VERSION "1.0"

NS_ :

BS_:
BU_:

CM_ "For Preparatory CareFree Awning Messages
Author: Damiano Liviero
for Winnebago Industries Inc.
";

CM_ "1FDCD";
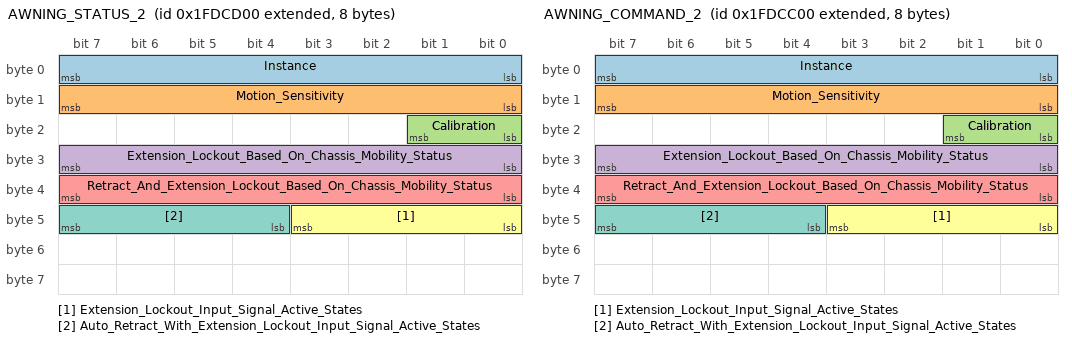
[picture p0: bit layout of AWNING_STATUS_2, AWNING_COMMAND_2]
BO_ 2180893952 AWNING_STATUS_2: 8  Vector__XXX
    SG_ Instance:        0|8@1+  (1,0)   [0|255] ""    Vector__XXX
    SG_ Motion_Sensitivity:        8|8@1+  (0.5,0)   [0|255] "%"    Vector__XXX
    SG_ Calibration:        16|2@1+  (1,0)   [0|3] ""    Vector__XXX
    SG_ Extension_Lockout_Based_On_Chassis_Mobility_Status:        24|8@1+  (1,0)   [0|255] ""    Vector__XXX
    SG_ Retract_And_Extension_Lockout_Based_On_Chassis_Mobility_Status:        32|8@1+  (1,0)   [0|255] ""    Vector__XXX
    SG_ Extension_Lockout_Input_Signal_Active_States:        40|4@1+  (1,0)   [0|15] ""    Vector__XXX
    SG_ Auto_Retract_With_Extension_Lockout_Input_Signal_Active_States:        44|4@1+  (1,0)   [0|15] ""    Vector__XXX

    0 "Least Sensitive"
    200 "Most Sensitive"
    255 "Data Invalid";

    0 "Uncalibrated"
    1 "Calibrated"
    3 "Data Invalid";

    0 "Must be set to 0"
    1 "Park brake (Extension lockout when park brake off)"
    2 "Transmission lock (Extension lockout when engine free to start)"
    3 "Engine lock status (Extension lockout when engine free to start)"
    4 "Ignition switch status (Extension lockout when ignition switch On)"
    5 "Accessory switch status (Extension lockout when accessory switch On)"
    6 "Transmission current gear (Extension lockout when not in Park or Neutral)"
    7 "Transmission gear selected (Extension lockout when not in Park or Neutral)"
    255 "Data Invalid";

    0 "Must be set to 0"
    1 "Park brake (RTL when park brake off)"
    2 "Transmission lock (RTL when transmission not locked)"
    3 "Engine lock status (RTL when engine free to start)"
    4 "Ignition switch status (RTL when ignition switch On)"
    5 "Accessory switch status (RTL when accessory switch On)"
    6 "Transmission current gear (RTL when not in Park or Neutral)"
    7 "Transmission gear selected (RTL when not in Park or Neutral)"
    255 "Data Invalid";

    0 "Input Disabled"
    1 "Active when input Low"
    2 "Active when input High"
    3 "Active when input either Low or High"
    4 "Active when input Floating"
    5 "Active when input Floating and Low"
    6 "Active when input Floating and High"
    15 "Data Invalid";

    0 "Input Disabled"
    1 "Active when input Low"
    2 "Active when input High"
    3 "Active when input either Low or High"
    4 "Active when input Floating"
    5 "Active when input Floating and Low"
    6 "Active when input Floating and High"
    15 "Data Invalid";

CM_ "1FDCC";
BO_ 2180893696 AWNING_COMMAND_2: 8  Vector__XXX
    SG_ Instance:        0|8@1+  (1,0)   [0|255] ""    Vector__XXX
    SG_ Motion_Sensitivity:        8|8@1+  (0.5,0)   [0|255] "%"    Vector__XXX
    SG_ Calibration:        16|2@1+  (1,0)   [0|3] ""    Vector__XXX
    SG_ Extension_Lockout_Based_On_Chassis_Mobility_Status:        24|8@1+  (1,0)   [0|255] ""    Vector__XXX
    SG_ Retract_And_Extension_Lockout_Based_On_Chassis_Mobility_Status:        32|8@1+  (1,0)   [0|255] ""    Vector__XXX
    SG_ Extension_Lockout_Input_Signal_Active_States:        40|4@1+  (1,0)   [0|15] ""    Vector__XXX
    SG_ Auto_Retract_With_Extension_Lockout_Input_Signal_Active_States:        44|4@1+  (1,0)   [0|15] ""    Vector__XXX

    0 "Least Sensitive"
    200 "Most Sensitive"
    255 "Data Invalid";

    0 "Initiate calibration routine"
    3 "Data Invalid";

    0 "Must be set to 0"
    1 "Park brake (Extension lockout when park brake off)"
    2 "Transmission lock (Extension lockout when engine free to start)"
    3 "Engine lock status (Extension lockout when engine free to start)"
    4 "Ignition switch status (Extension lockout when ignition switch On)"
    5 "Accessory switch status (Extension lockout when accessory switch On)"
    6 "Transmission current gear (Extension lockout when not in Park or Neutral)"
    7 "Transmission gear selected (Extension lockout when not in Park or Neutral)"
    255 "Data Invalid";

    0 "Must be set to 0"
    1 "Park brake (RTL when park brake off)"
    2 "Transmission lock (RTL when transmission not locked)"
    3 "Engine lock status (RTL when engine free to start)"
    4 "Ignition switch status (RTL when ignition switch On)"
    5 "Accessory switch status (RTL when accessory switch On)"
    6 "Transmission current gear (RTL when not in Park or Neutral)"
    7 "Transmission gear selected (RTL when not in Park or Neutral)"
    255 "Data Invalid";

    0 "Input Disabled"
    1 "Active when input Low"
    2 "Active when input High"
    3 "Active when input either Low or High"
    4 "Active when input Floating"
    5 "Active when input Floating and Low"
    6 "Active when input Floating and High"
    15 "Data Invalid";

    0 "Input Disabled"
    1 "Active when input Low"
    2 "Active when input High"
    3 "Active when input either Low or High"
    4 "Active when input Floating"
    5 "Active when input Floating and Low"
    6 "Active when input Floating and High"
    15 "Data Invalid";
